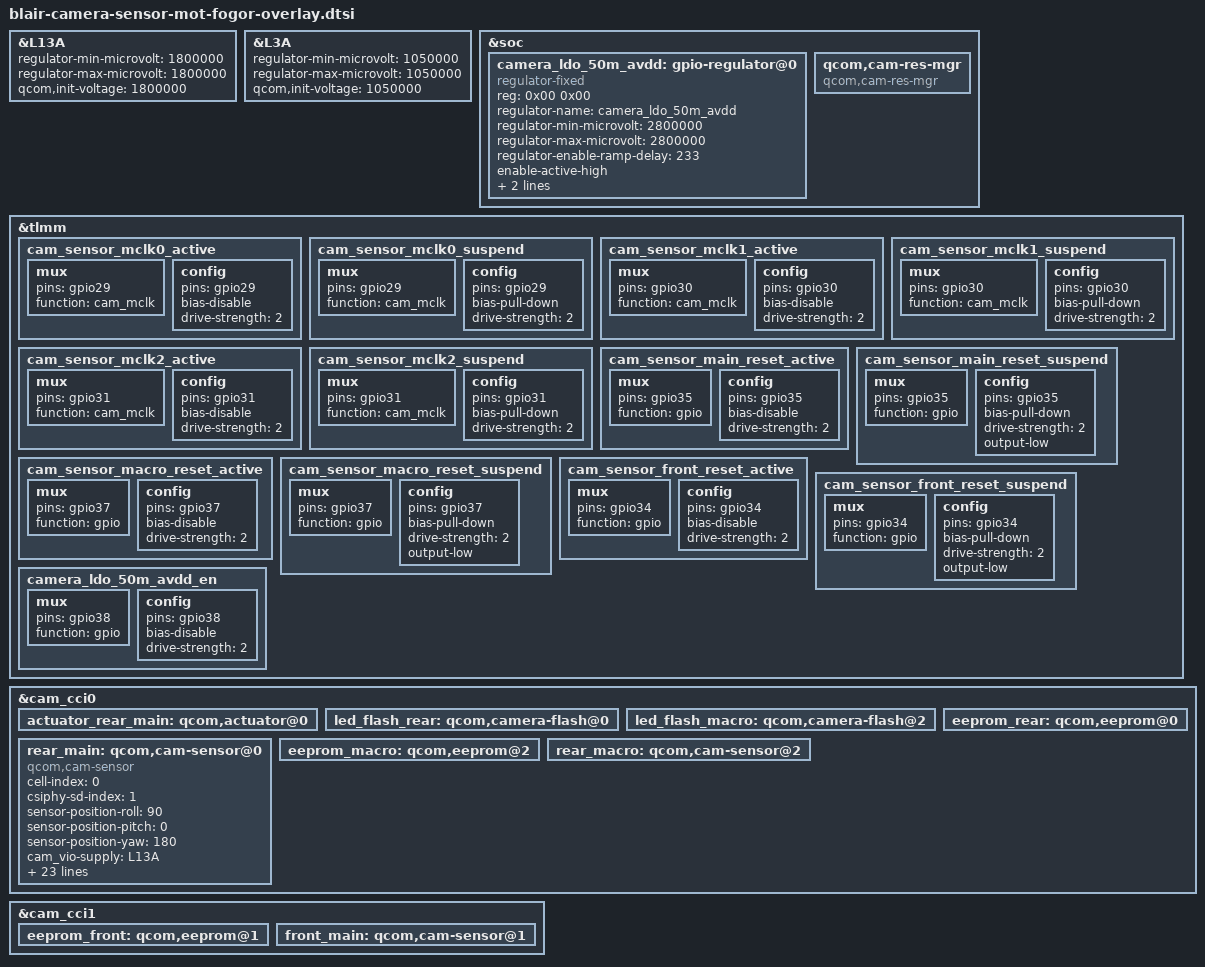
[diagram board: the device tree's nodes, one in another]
#include <dt-bindings/clock/qcom,gcc-blair.h>
#include <dt-bindings/msm/msm-camera.h>

/*s5kjns afvdd en*/

/*s5kjns s5k4h7 sc202acs iovdd*/
&L13A{
  regulator-min-microvolt = <1800000>;
  regulator-max-microvolt = <1800000>;
  qcom,init-voltage = <1800000>;
  status = "okay";
};

/*s5kjns dvdd*/
&L3A{
  regulator-min-microvolt = <1050000>;
  regulator-max-microvolt = <1050000>;
  qcom,init-voltage = <1050000>;
  status = "okay";
};

&soc {
  /*s5kjns avdd*/
  camera_ldo_50m_avdd: gpio-regulator@0 {
    compatible = "regulator-fixed";
    reg = <0x00 0x00>;
    regulator-name = "camera_ldo_50m_avdd";
    regulator-min-microvolt = <2800000>;
    regulator-max-microvolt = <2800000>;
    regulator-enable-ramp-delay = <233>;
    enable-active-high;
    gpio = <&tlmm 38 0>;
    pinctrl-names = "default";
    pinctrl-0 = <&camera_ldo_50m_avdd_en>;
    // vin-supply = <&vph_pwr>;
  };

  /*sc202acs avdd*/

  /*s5k4h7 avdd*/

  /*s5k4h7 dvdd*/

  /* s5kjns afvdd */

  /* flash iovdd */

  qcom,cam-res-mgr {
    compatible = "qcom,cam-res-mgr";
    status = "ok";
  };
};

&tlmm {
/* flash iovdd enable */

  cam_sensor_mclk0_active: cam_sensor_mclk0_active {
    mux {
      pins = "gpio29";
      function = "cam_mclk";
    };

    config {
      pins = "gpio29";
      bias-disable; /* No PULL */
      drive-strength = <2>; /* 2 MA */
    };
  };

  cam_sensor_mclk0_suspend: cam_sensor_mclk0_suspend {
    mux {
      pins = "gpio29";
      function = "cam_mclk";
    };

    config {
      pins = "gpio29";
      bias-pull-down; /* PULL DOWN */
      drive-strength = <2>; /* 2 MA */
    };
  };

  cam_sensor_mclk1_active: cam_sensor_mclk1_active {
    mux {
      pins = "gpio30";
      function = "cam_mclk";
    };

    config {
      pins = "gpio30";
      bias-disable; /* No PULL */
      drive-strength = <2>; /* 2 MA */
    };
  };

  cam_sensor_mclk1_suspend: cam_sensor_mclk1_suspend {
    mux {
      pins = "gpio30";
      function = "cam_mclk";
    };

    config {
      pins = "gpio30";
      bias-pull-down; /* PULL DOWN */
      drive-strength = <2>; /* 2 MA */
    };
  };

  cam_sensor_mclk2_active: cam_sensor_mclk2_active {
    mux {
      pins = "gpio31";
      function = "cam_mclk";
    };

    config {
      pins = "gpio31";
      bias-disable; /* No PULL */
      drive-strength = <2>;
    };
  };

  cam_sensor_mclk2_suspend: cam_sensor_mclk2_suspend {
    mux {
      pins = "gpio31";
      function = "cam_mclk";
    };

    config {
      pins = "gpio31";
      bias-pull-down; /* PULL DOWN */
      drive-strength = <2>;
    };
  };

  cam_sensor_main_reset_active: cam_sensor_main_reset_active {
    mux {
      pins = "gpio35";
      function = "gpio";
    };

    config {
      pins = "gpio35";
      bias-disable; /* No PULL */
      drive-strength = <2>; /* 2 MA */
    };
  };

  cam_sensor_main_reset_suspend: cam_sensor_main_reset_suspend {
    mux {
      pins = "gpio35";
      function = "gpio";
    };

    config {
      pins = "gpio35";
      bias-pull-down; /* PULL DOWN */
      drive-strength = <2>; /* 2 MA */
      output-low;
    };
  };
  cam_sensor_macro_reset_active: cam_sensor_macro_reset_active {
    mux {
      pins = "gpio37";
      function = "gpio";
    };

    config {
      pins = "gpio37";
      bias-disable; /* No PULL */
      drive-strength = <2>; /* 2 MA */
    };
  };

  cam_sensor_macro_reset_suspend: cam_sensor_macro_reset_suspend {
    mux {
      pins = "gpio37";
      function = "gpio";
    };

    config {
      pins = "gpio37";
      bias-pull-down; /* PULL DOWN */
      drive-strength = <2>; /* 2 MA */
      output-low;
    };
  };
  cam_sensor_front_reset_active: cam_sensor_front_reset_active {
    mux {
      pins = "gpio34";
      function = "gpio";
    };

    config {
      pins = "gpio34";
      bias-disable; /* No PULL */
      drive-strength = <2>; /* 2 MA */
    };
  };

  cam_sensor_front_reset_suspend: cam_sensor_front_reset_suspend {
    mux {
      pins = "gpio34";
      function = "gpio";
    };

    config {
      pins = "gpio34";
      bias-pull-down; /* PULL DOWN */
      drive-strength = <2>; /* 2 MA */
      output-low;
    };
  };

/* s5kjns avdd enable */
  camera_ldo_50m_avdd_en: camera_ldo_50m_avdd_en {
    mux {
      pins = "gpio38";
      function = "gpio";
    };

    config {
      pins = "gpio38";
      bias-disable; /* No PULL */
      drive-strength = <2>; /* 2 MA */
    };
  };

/* sc202acs avdd enable */

/* s5k4h7 dvdd enable */

/* s5k4h7 avdd enable */

};

&cam_cci0 {
  /* Rear 50M AF */
  actuator_rear_main:qcom,actuator@0{

  };

  /* Rear 50M FLASH */
  led_flash_rear: qcom,camera-flash@0 {

  };

  /* MACRO 2m FLASH */
  led_flash_macro: qcom,camera-flash@2 {

  };

  /* Rear s5kjns eeprom */
  eeprom_rear: qcom,eeprom@0 {

  };

  /* Rear s5kjns */
  rear_main: qcom,cam-sensor@0 {
    cell-index = <0>;
    compatible = "qcom,cam-sensor";
    csiphy-sd-index = <1>;
    sensor-position-roll = <90>;
    sensor-position-pitch = <0>;
    sensor-position-yaw = <180>;
    // actuator-src = <&actuator_rear_main>;
    // eeprom-src = <&eeprom_rear>;
    cam_vio-supply = <&L13A>;
    cam_vana-supply = <&camera_ldo_50m_avdd>;
    cam_vdig-supply = <&L3A>;
    cam_clk-supply = <&gcc_camss_top_gdsc>;
    regulator-names ="cam_vio", "cam_vana", "cam_vdig",
      "cam_clk";
    rgltr-cntrl-support;
    rgltr-min-voltage = <1800000 2800000 1050000 0>;
    rgltr-max-voltage = <1800000 2800000 1050000 0>;
    rgltr-load-current = <120000 80000 1200000 0>;
    gpio-no-mux = <0>;
    pinctrl-names = "cam_default", "cam_suspend";
    pinctrl-0 = <&cam_sensor_mclk0_active
        &cam_sensor_main_reset_active>;
    pinctrl-1 = <&cam_sensor_mclk0_suspend
        &cam_sensor_main_reset_suspend>;
    gpios = <&tlmm 29 0>,
      <&tlmm 35 0>;
    gpio-reset = <1>;
    gpio-req-tbl-num = <0 1>;
    gpio-req-tbl-flags = <1 0>;
    gpio-req-tbl-label = "CAMIF_MCLK0",
          "CAM_RESET1";
    cci-master = <0>;
    status = "ok";
    clocks = <&gcc GCC_CAMSS_MCLK0_CLK>;
    clock-names = "cam_clk";
    clock-cntl-level = "turbo";
    clock-rates = <24000000>;
  };

  /* Rear sc202acs otp */
  eeprom_macro: qcom,eeprom@2 {

  };

  /* Rear sc202acs */
  rear_macro: qcom,cam-sensor@2 {

  };

};

&cam_cci1 {
  /* Front s5k4h7 otp */
  eeprom_front: qcom,eeprom@1 {

  };

  /*Front s5k4h7*/
  front_main: qcom,cam-sensor@1 {

  };
};
